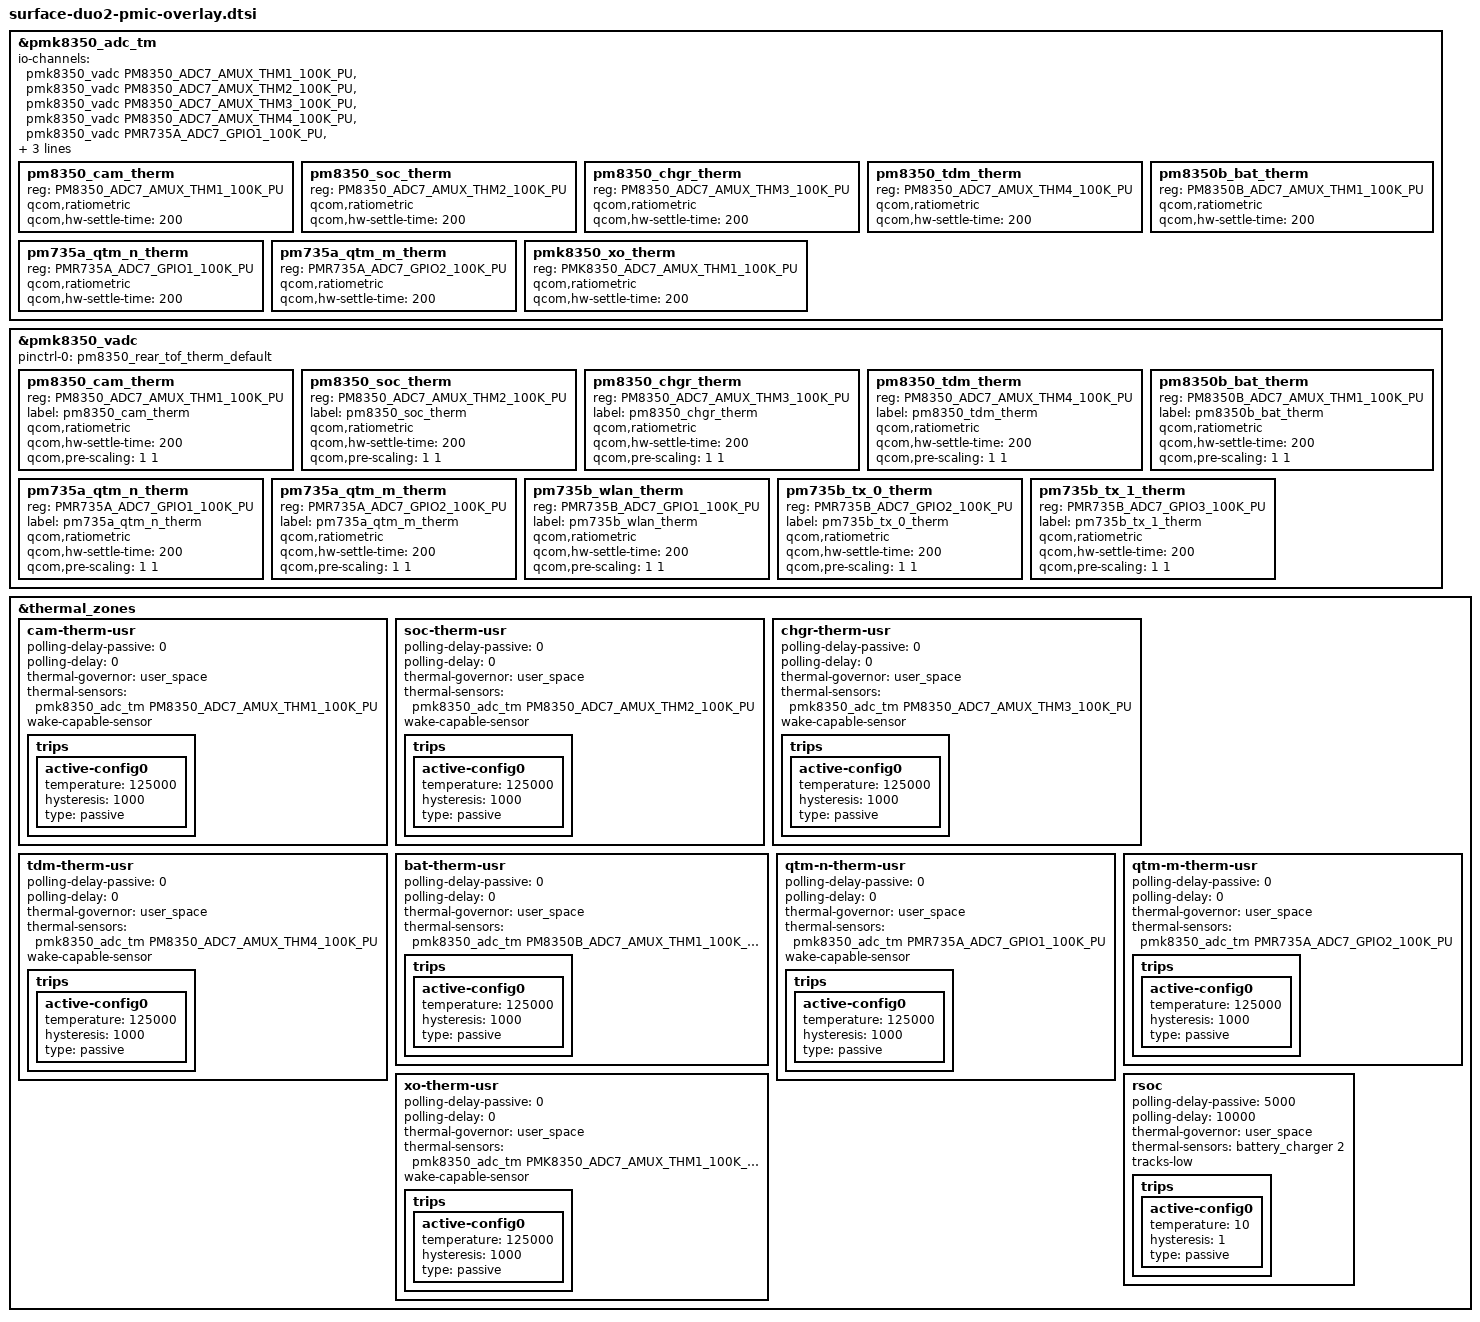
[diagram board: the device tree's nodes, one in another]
/*
 * Copyright (c) 2020 Microsoft Corporation
 *
 * This program is free software; you can redistribute it and/or modify it
 * under the terms of the GNU General Public License version 2 as published by
 * the Free Software Foundation.
 */




&pmk8350_adc_tm {
	io-channels = <&pmk8350_vadc PM8350_ADC7_AMUX_THM1_100K_PU>,
			<&pmk8350_vadc PM8350_ADC7_AMUX_THM2_100K_PU>,
			<&pmk8350_vadc PM8350_ADC7_AMUX_THM3_100K_PU>,
			<&pmk8350_vadc PM8350_ADC7_AMUX_THM4_100K_PU>,
			<&pmk8350_vadc PMR735A_ADC7_GPIO1_100K_PU>,
			<&pmk8350_vadc PM8350B_ADC7_AMUX_THM1_100K_PU>,
			<&pmk8350_vadc PMR735A_ADC7_GPIO2_100K_PU>,
			<&pmk8350_vadc PMK8350_ADC7_AMUX_THM1_100K_PU>;

	pm8350_cam_therm {
		reg = <PM8350_ADC7_AMUX_THM1_100K_PU>;
		qcom,ratiometric;
		qcom,hw-settle-time = <200>;
	};

	pm8350_soc_therm {
		reg = <PM8350_ADC7_AMUX_THM2_100K_PU>;
		qcom,ratiometric;
		qcom,hw-settle-time = <200>;
	};

	pm8350_chgr_therm {
		reg = <PM8350_ADC7_AMUX_THM3_100K_PU>;
		qcom,ratiometric;
		qcom,hw-settle-time = <200>;
	};

	pm8350_tdm_therm {
		reg = <PM8350_ADC7_AMUX_THM4_100K_PU>;
		qcom,ratiometric;
		qcom,hw-settle-time = <200>;
	};

	pm8350b_bat_therm {
		reg = <PM8350B_ADC7_AMUX_THM1_100K_PU>;
		qcom,ratiometric;
		qcom,hw-settle-time = <200>;
	};

	pm735a_qtm_n_therm {
		reg = <PMR735A_ADC7_GPIO1_100K_PU>;
		qcom,ratiometric;
		qcom,hw-settle-time = <200>;
	};

	pm735a_qtm_m_therm {
		reg = <PMR735A_ADC7_GPIO2_100K_PU>;
		qcom,ratiometric;
		qcom,hw-settle-time = <200>;
	};

	pmk8350_xo_therm {
		reg = <PMK8350_ADC7_AMUX_THM1_100K_PU>;
		qcom,ratiometric;
		qcom,hw-settle-time = <200>;
	};

};


&pmk8350_vadc {

	pinctrl-names = "default";
	pinctrl-0 = <&pm8350_rear_tof_therm_default>;

	pm8350_cam_therm {
		reg = <PM8350_ADC7_AMUX_THM1_100K_PU>;
		label = "pm8350_cam_therm";
		qcom,ratiometric;
		qcom,hw-settle-time = <200>;
		qcom,pre-scaling = <1 1>;
	};

	pm8350_soc_therm {
		reg = <PM8350_ADC7_AMUX_THM2_100K_PU>;
		label = "pm8350_soc_therm";
		qcom,ratiometric;
		qcom,hw-settle-time = <200>;
		qcom,pre-scaling = <1 1>;
	};

	pm8350_chgr_therm {
		reg = <PM8350_ADC7_AMUX_THM3_100K_PU>;
		label = "pm8350_chgr_therm";
		qcom,ratiometric;
		qcom,hw-settle-time = <200>;
		qcom,pre-scaling = <1 1>;
	};

	pm8350_tdm_therm {
		reg = <PM8350_ADC7_AMUX_THM4_100K_PU>;
		label = "pm8350_tdm_therm";
		qcom,ratiometric;
		qcom,hw-settle-time = <200>;
		qcom,pre-scaling = <1 1>;
	};

	pm8350b_bat_therm {
		reg = <PM8350B_ADC7_AMUX_THM1_100K_PU>;
		label = "pm8350b_bat_therm";
		qcom,ratiometric;
		qcom,hw-settle-time = <200>;
		qcom,pre-scaling = <1 1>;
	};

	pm735a_qtm_n_therm {
		reg = <PMR735A_ADC7_GPIO1_100K_PU>;
		label = "pm735a_qtm_n_therm";
		qcom,ratiometric;
		qcom,hw-settle-time = <200>;
		qcom,pre-scaling = <1 1>;
	};

	pm735a_qtm_m_therm {
		reg = <PMR735A_ADC7_GPIO2_100K_PU>;
		label = "pm735a_qtm_m_therm";
		qcom,ratiometric;
		qcom,hw-settle-time = <200>;
		qcom,pre-scaling = <1 1>;
	};

	pm735b_wlan_therm {
		reg = <PMR735B_ADC7_GPIO1_100K_PU>;
		label = "pm735b_wlan_therm";
		qcom,ratiometric;
		qcom,hw-settle-time = <200>;
		qcom,pre-scaling = <1 1>;
	};

	pm735b_tx_0_therm {
		reg = <PMR735B_ADC7_GPIO2_100K_PU>;
		label = "pm735b_tx_0_therm";
		qcom,ratiometric;
		qcom,hw-settle-time = <200>;
		qcom,pre-scaling = <1 1>;
	};

	pm735b_tx_1_therm {
		reg = <PMR735B_ADC7_GPIO3_100K_PU>;
		label = "pm735b_tx_1_therm";
		qcom,ratiometric;
		qcom,hw-settle-time = <200>;
		qcom,pre-scaling = <1 1>;
	};

};

&thermal_zones {
	cam-therm-usr {
		polling-delay-passive = <0>;
		polling-delay = <0>;
		thermal-governor = "user_space";
		thermal-sensors = <&pmk8350_adc_tm PM8350_ADC7_AMUX_THM1_100K_PU>;
		wake-capable-sensor;
		trips {
			active-config0 {
				temperature = <125000>;
				hysteresis = <1000>;
				type = "passive";
			};
		};
	};

	soc-therm-usr {
		polling-delay-passive = <0>;
		polling-delay = <0>;
		thermal-governor = "user_space";
		thermal-sensors = <&pmk8350_adc_tm PM8350_ADC7_AMUX_THM2_100K_PU>;
		wake-capable-sensor;
		trips {
			active-config0 {
				temperature = <125000>;
				hysteresis = <1000>;
				type = "passive";
			};
		};
	};

	chgr-therm-usr {
		polling-delay-passive = <0>;
		polling-delay = <0>;
		thermal-governor = "user_space";
		thermal-sensors = <&pmk8350_adc_tm PM8350_ADC7_AMUX_THM3_100K_PU>;
		wake-capable-sensor;
		trips {
			active-config0 {
				temperature = <125000>;
				hysteresis = <1000>;
				type = "passive";
			};
		};
	};

	tdm-therm-usr {
		polling-delay-passive = <0>;
		polling-delay = <0>;
		thermal-governor = "user_space";
		thermal-sensors = <&pmk8350_adc_tm PM8350_ADC7_AMUX_THM4_100K_PU>;
		wake-capable-sensor;
		trips {
			active-config0 {
				temperature = <125000>;
				hysteresis = <1000>;
				type = "passive";
			};
		};
	};

	bat-therm-usr{
        polling-delay-passive = <0>;
		polling-delay = <0>;
		thermal-governor = "user_space";
		thermal-sensors = <&pmk8350_adc_tm PM8350B_ADC7_AMUX_THM1_100K_PU>;
				trips {
			active-config0 {
				temperature = <125000>;
				hysteresis = <1000>;
				type = "passive";
			};
		};
	};

	qtm-n-therm-usr {
		polling-delay-passive = <0>;
		polling-delay = <0>;
		thermal-governor = "user_space";
		thermal-sensors = <&pmk8350_adc_tm PMR735A_ADC7_GPIO1_100K_PU>;
		wake-capable-sensor;
		trips {
			active-config0 {
				temperature = <125000>;
				hysteresis = <1000>;
				type = "passive";
			};
		};
	};

	qtm-m-therm-usr{
        polling-delay-passive = <0>;
		polling-delay = <0>;
		thermal-governor = "user_space";
		thermal-sensors = <&pmk8350_adc_tm PMR735A_ADC7_GPIO2_100K_PU>;
				trips {
			active-config0 {
				temperature = <125000>;
				hysteresis = <1000>;
				type = "passive";
			};
		};
	};

	xo-therm-usr {
		polling-delay-passive = <0>;
		polling-delay = <0>;
		thermal-governor = "user_space";
		thermal-sensors = <&pmk8350_adc_tm PMK8350_ADC7_AMUX_THM1_100K_PU>;
		wake-capable-sensor;
		trips {
			active-config0 {
				temperature = <125000>;
				hysteresis = <1000>;
				type = "passive";
			};
		};
	};
/*
	fg-pack1 {
		polling-delay-passive = <250>;
		polling-delay = <10000>;
		thermal-governor = "user_space";
		thermal-sensors = <&battery_charger 0>;
		wake-capable-sensor;
		trips {
			active-config0 {
				temperature = <125000>;
				hysteresis = <1000>;
				type = "passive";
			};
		};
	};

	fg-pack2 {
		polling-delay-passive = <250>;
		polling-delay = <10000>;
		thermal-governor = "user_space";
		thermal-sensors = <&battery_charger 1>;
		wake-capable-sensor;
		trips {
			active-config0 {
				temperature = <125000>;
				hysteresis = <1000>;
				type = "passive";
			};
		};
	};
*/
	rsoc {
		polling-delay-passive = <5000>;
		polling-delay = <10000>;
		thermal-governor = "user_space";
		thermal-sensors = <&battery_charger 2>;
		tracks-low;

		trips {
			active-config0 {
				temperature = <10>;
				hysteresis = <1>;
				type = "passive";
			};
		};
	};

};
